VERSION "TOOL OF INVENTEC AND KOSTAL"

NS_ :

BS_:

BU_: CAPL_Debug

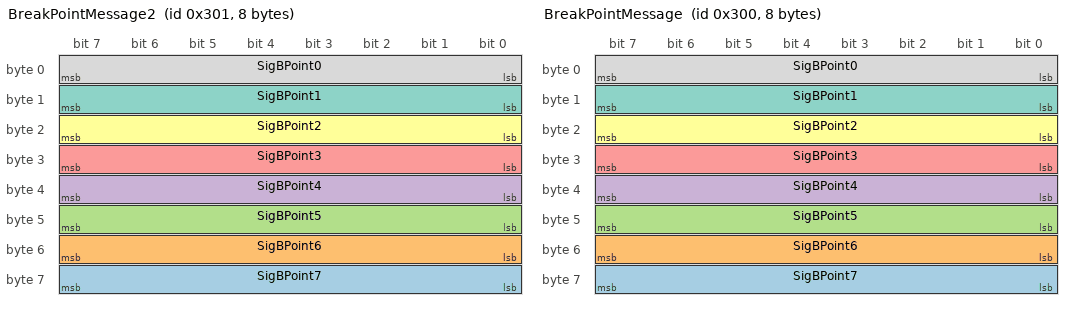
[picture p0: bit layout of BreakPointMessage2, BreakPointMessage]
BO_ 769 BreakPointMessage2: 8 Vector__XXX
 SG_ SigBPoint7 : 56|8@1+ (1,0) [0|0] ""  Vector__XXX
 SG_ SigBPoint6 : 48|8@1+ (1,0) [0|0] ""  Vector__XXX
 SG_ SigBPoint5 : 40|8@1+ (1,0) [0|0] ""  Vector__XXX
 SG_ SigBPoint4 : 32|8@1+ (1,0) [0|0] ""  Vector__XXX
 SG_ SigBPoint3 : 24|8@1+ (1,0) [0|0] ""  Vector__XXX
 SG_ SigBPoint2 : 16|8@1+ (1,0) [0|0] ""  Vector__XXX
 SG_ SigBPoint1 : 8|8@1+ (1,0) [0|0] ""  Vector__XXX
 SG_ SigBPoint0 : 0|8@1+ (1,0) [0|0] ""  Vector__XXX

BO_ 768 BreakPointMessage: 8 Vector__XXX
 SG_ SigBPoint7 : 56|8@1+ (1,0) [0|0] ""  Vector__XXX
 SG_ SigBPoint6 : 48|8@1+ (1,0) [0|0] ""  Vector__XXX
 SG_ SigBPoint5 : 40|8@1+ (1,0) [0|0] ""  Vector__XXX
 SG_ SigBPoint4 : 32|8@1+ (1,0) [0|0] ""  Vector__XXX
 SG_ SigBPoint3 : 24|8@1+ (1,0) [0|0] ""  Vector__XXX
 SG_ SigBPoint2 : 16|8@1+ (1,0) [0|0] ""  Vector__XXX
 SG_ SigBPoint1 : 8|8@1+ (1,0) [0|0] ""  Vector__XXX
 SG_ SigBPoint0 : 0|8@1+ (1,0) [0|0] ""  Vector__XXX

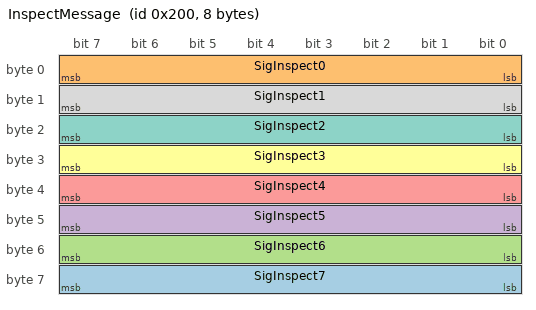
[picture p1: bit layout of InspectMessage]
BO_ 512 InspectMessage: 8 Vector__XXX
 SG_ SigInspect7 : 56|8@1+ (1,0) [0|0] ""  Vector__XXX
 SG_ SigInspect0 : 0|8@1+ (1,0) [0|0] ""  Vector__XXX
 SG_ SigInspect6 : 48|8@1+ (1,0) [0|0] ""  Vector__XXX
 SG_ SigInspect5 : 40|8@1+ (1,0) [0|0] ""  Vector__XXX
 SG_ SigInspect4 : 32|8@1+ (1,0) [0|0] ""  Vector__XXX
 SG_ SigInspect3 : 24|8@1+ (1,0) [0|0] ""  Vector__XXX
 SG_ SigInspect2 : 16|8@1+ (1,0) [0|0] ""  Vector__XXX
 SG_ SigInspect1 : 8|8@1+ (1,0) [0|0] ""  Vector__XXX
